# CY8C5868AXI_LP035 register map
File version: 0.1
CY8C58LP
Registers are 8-bit, read-write, no defined reset value unless marked. A register's access mark holds for its fields unless they carry their own. Offsets are from the block's base; lines under a group give offsets from that group; [hi:lo] are bit positions; {n}, {i} and the like mark numbered series; 'fields as' and 'values as' point back to an identical list; <NAME> marks a mode.

## Memory map
0x400043A3 PWM_MOTOR_TILT size 0xB7C
0x400043A3 Counter_LED size 0xB64
0x400043A3 PWM_MOTOR_PAN size 0xB70
0x400043A4 WaveDAC8_BuffAmp size 0x17A2
0x400043A8 VDAC8_ANAPOS size 0x17DA
0x400043A8 WaveDAC8_VDAC8 size 0x17DB
0x400043A9 PGA_ASTIM size 0x17AE
0x400043AA ADC size 0x17E0
0x400049C8 I2C_COULOMB size 0x19
0x40006402 QuadDec_TILT size 0x165
0x40006402 QuadDec_TILT_Cnt16 size 0x93
0x40006421 UART_USB size 0x148 — UART
0x40006465 Status_Reg_SYS size 0x31
0x40006468 Status_Reg_MOTORS size 0x31
0x40006474 Control_Reg_LED size 0x1
0x40006476 Control_Reg_LORA_RESET size 0x1
0x40006478 Control_Reg_BUZ size 0x1
0x40006479 Control_Reg_WS size 0x1
0x40006506 QuadDec_PAN size 0x5F
0x40006506 QuadDec_PAN_Cnt16 size 0x92
0x40006565 Status_Reg_BUTTON size 0x31
0x40006574 Control_Reg_MOTOR size 0x1
0x40006575 Control_Reg_LORA size 0x1
0x40006576 Control_Reg_SYS size 0x1

## PWM_MOTOR_TILT
Base 0x400043A3
0x00 PWM_MOTOR_TILT_GLOBAL_ENABLE — PM.ACT.CFG
  [3:0] en_timer — Enable timer/counters.
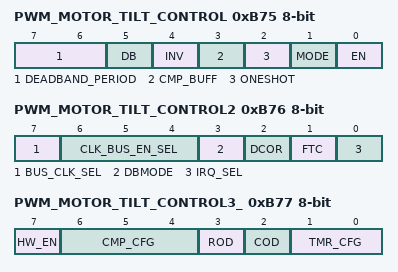
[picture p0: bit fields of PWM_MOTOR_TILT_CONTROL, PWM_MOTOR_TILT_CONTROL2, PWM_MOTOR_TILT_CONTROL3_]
0xB75 PWM_MOTOR_TILT_CONTROL — TMRx.CFG0
  [7:6] DEADBAND_PERIOD
  [5] DB — Deadband mode--Deadband phases phi1 and phi2 are outputted on CMP and TC output pins respectively.
    0=Timer (CMP and TC are output.); 1=Deadband (PHI1 (instead of CMP) and PHI2 (instead of TC) are output.)
  [4] INV — Invert sense of TIMEREN signal
  [3] CMP_BUFF — Buffer compare register. Compare register updates only on timer terminal count.
  [2] ONESHOT — Timer stops upon reaching stop condition defined by TMR_CFG bits. Can be restarted by asserting TIMER RESET or disabling and re-enabling block.
  [1] MODE ro — Mode. (0 = Timer; 1 = Comparator)
    0=Timer mode. CNT/CMP register holds timer count value.; 1=Comparator mode. CNT/CMP register holds comparator threshold value.
  [0] EN — Enables timer/comparator.
0xB76 PWM_MOTOR_TILT_CONTROL2 — TMRx.CFG1
  [7] BUS_CLK_SEL — Bus Clock selection.
  [6:4] CLK_BUS_EN_SEL — Digital Global Clock selection.
  [3] DBMODE — Deadband mode (asynchronous/synchronous). CMP output pin is also affected when not in deadband mode (CFG0.DEADBAND).
  [2] DCOR — Disable Clear on Read (DCOR) of Status Register SR0.
  [1] FTC — First Terminal Count (FTC). Setting this bit forces a single pulse on the TC pin when first enabled.
    0=Disable_FTC (Disable the single cycle pulse, which signifies the timer is starting.); 1=Enable_FTC (Enable the single cycle pulse, which signifies the timer is starting.)
  [0] IRQ_SEL — Irq selection. (0 = raw interrupts; 1 = status register interrupts)
0xB77 PWM_MOTOR_TILT_CONTROL3_ — TMRx.CFG2
  [7] HW_EN — When set Timer Enable controls counting.
  [6:4] CMP_CFG — Comparator configurations
    0=Equal (Compare Equal); 1=Less_than (Compare Less Than); 2=Less_than_or_equal (Compare Less Than or Equal .); 3=Greater (Compare Greater Than .); 4=Greater_than_or_equal (Compare Greater Than or Equal)
  [3] ROD — Reset On Disable (ROD). Resets internal state of output logic
  [2] COD — Clear On Disable (COD). Clears or gates outputs to zero.
  [1:0] TMR_CFG — Timer configuration (MODE = 0): 000 = Continuous; 001 = Pulsewidth; 010 = Period; 011 = Stop on IRQ
    0=Continuous (Timer runs while EN bit of CFG0 register is set to '1'.); 1=Pulsewidth (Timer runs from positive to negative edge of TIMEREN.); 2=Period (Timer runs from positive to positive edge of TIMEREN.); 3=Irq (Timer runs until IRQ.)
0xB79 PWM_MOTOR_TILT_PERIOD 16-bit — TMRx.PER0 - Assigned Period
0xB7B PWM_MOTOR_TILT_COMPARE 16-bit — TMRx.CNT_CMP0 - Assigned Compare Value

## Status_Reg_SYS
Base 0x40006465
0x00 Status_Reg_SYS_STATUS_REG
0x20 Status_Reg_SYS_MASK_REG
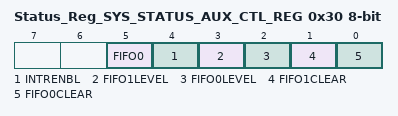
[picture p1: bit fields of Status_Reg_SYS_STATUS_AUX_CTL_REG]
0x30 Status_Reg_SYS_STATUS_AUX_CTL_REG
  [5] FIFO0 — FIFO0 clear
    1=ENABLED (Enable counter); 0=DISABLED (Disable counter)
  [4] INTRENBL — Enables or disables the Interrupt
    1=ENABLED (Interrupt enabled); 0=DISABLED (Interrupt disabled)
  [3] FIFO1LEVEL — FIFO level
    1=ENABLED (FIFO LVL: input mode: FIFO at least 1/2 empty; output mode: FIFO at least 1/2 full); 0=DISABLED (FIFO LVL: input mode: FIFO not full; output mode: FIFO not empty)
  [2] FIFO0LEVEL — FIFO level
    values as FIFO1LEVEL
  [1] FIFO1CLEAR — FIFO clear
    1=ENABLED (Clear FIFO state); 0=DISABLED (Normal FIFO operation)
  [0] FIFO0CLEAR — FIFO clear
    values as FIFO1CLEAR

## Status_Reg_MOTORS
Base 0x40006468
Registers as Status_Reg_SYS (with Status_Reg_SYS read as Status_Reg_MOTORS).

## Status_Reg_BUTTON
Base 0x40006565
Registers as Status_Reg_SYS (with Status_Reg_SYS read as Status_Reg_BUTTON).
